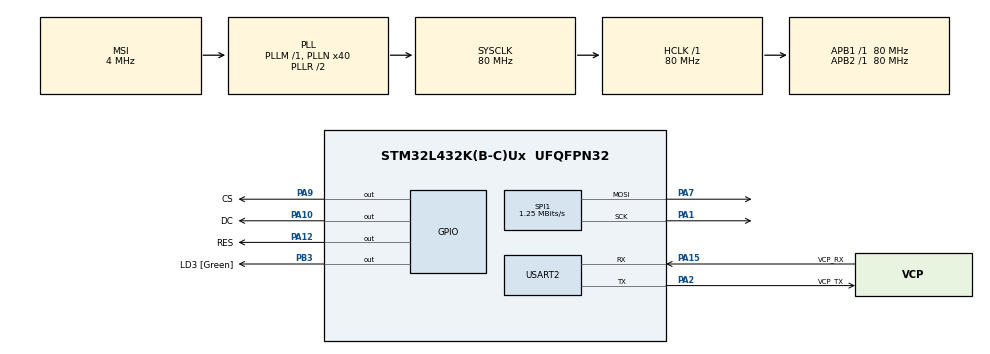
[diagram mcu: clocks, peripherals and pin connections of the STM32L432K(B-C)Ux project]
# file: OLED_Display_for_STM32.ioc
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Mcu.Family=STM32L4
Mcu.Name=STM32L432K(B-C)Ux
Mcu.Package=UFQFPN32
NVIC.PriorityGroup=NVIC_PRIORITYGROUP_4
NVIC.SPI1_IRQn=true\:0\:0\:false\:false\:true\:true\:true\:true
PA0.GPIO_Label=MCO [High speed clock in]
PA0.Mode=HSE-External-Clock-Source-for-LittleOrca
PA0.Signal=RCC_CK_IN
PA1.Mode=TX_Only_Simplex_Unidirect_Master
PA1.Signal=SPI1_SCK
PA10.GPIO_Label=DC
PA10.Signal=GPIO_Output
PA12.GPIO_Label=RES
PA12.Signal=GPIO_Output
PA13\ (JTMS-SWDIO).GPIO_Label=SWDIO
PA13\ (JTMS-SWDIO).Mode=Serial_Wire
PA13\ (JTMS-SWDIO).Signal=SYS_JTMS-SWDIO
PA14\ (JTCK-SWCLK).GPIO_Label=SWCLK
PA14\ (JTCK-SWCLK).Mode=Serial_Wire
PA14\ (JTCK-SWCLK).Signal=SYS_JTCK-SWCLK
PA15\ (JTDI).GPIO_Label=VCP_RX
PA15\ (JTDI).Mode=Asynchronous
PA15\ (JTDI).Signal=USART2_RX
PA2.GPIO_Label=VCP_TX
PA2.Mode=Asynchronous
PA2.Signal=USART2_TX
PA7.Mode=TX_Only_Simplex_Unidirect_Master
PA7.Signal=SPI1_MOSI
PA9.GPIO_Label=CS
PA9.Signal=GPIO_Output
PB3\ (JTDO-TRACESWO).GPIO_Label=LD3 [Green]
PB3\ (JTDO-TRACESWO).Signal=GPIO_Output
PC14-OSC32_IN\ (PC14).Mode=LSE-External-Oscillator
PC14-OSC32_IN\ (PC14).Signal=RCC_OSC32_IN
PC15-OSC32_OUT\ (PC15).Mode=LSE-External-Oscillator
PC15-OSC32_OUT\ (PC15).Signal=RCC_OSC32_OUT
ProjectManager.HeapSize=0x200
ProjectManager.StackSize=0x400
ProjectManager.TargetToolchain=STM32CubeIDE
RCC.AHBFreq_Value=80000000
RCC.APB1Freq_Value=80000000
RCC.APB1TimFreq_Value=80000000
RCC.APB2Freq_Value=80000000
RCC.APB2TimFreq_Value=80000000
RCC.CortexFreq_Value=80000000
RCC.HCLKFreq_Value=80000000
RCC.HSE_VALUE=8000000
RCC.HSI16_VALUE=16000000
RCC.HSI48_VALUE=48000000
RCC.HSI_VALUE=16000000
RCC.MSI_VALUE=4000000
RCC.PLLMUL=RCC_PLLMUL_4
RCC.PLLN=40
RCC.SYSCLKFreq_VALUE=80000000
RCC.SYSCLKSource=RCC_SYSCLKSOURCE_PLLCLK
RCC.VCOOutputFreq_Value=160000000
SPI1.BaudRatePrescaler=SPI_BAUDRATEPRESCALER_64
SPI1.CalculateBaudRate=1.25 MBits/s
SPI1.DataSize=SPI_DATASIZE_8BIT
SPI1.Direction=SPI_DIRECTION_2LINES
SPI1.Mode=SPI_MODE_MASTER
SPI1.VirtualType=VM_MASTER
USART2.VirtualMode-Asynchronous=VM_ASYNC
board=NUCLEO-L432KC

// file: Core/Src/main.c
/* USER CODE BEGIN Header */
/**
  ******************************************************************************
  * @file           : main.c
  * @brief          : Main program body
  ******************************************************************************
  * @attention
  *
  * Copyright (c) 2024 STMicroelectronics.
  * All rights reserved.
  *
  * This software is licensed under terms that can be found in the LICENSE file
  * in the root directory of this software component.
  * If no LICENSE file comes with this software, it is provided AS-IS.
  *
  ******************************************************************************
  */
/* USER CODE END Header */
#include "main.h"
#include "spi.h"
#include "usart.h"
#include "gpio.h"

/* USER CODE BEGIN Includes */
#include "oled.h"
/* USER CODE END Includes */

void SystemClock_Config(void);

int main(void) {
  /* USER CODE BEGIN 1 */
  uint8_t Msg[] = "Hello world!!!";
  /* USER CODE END 1 */

  /* MCU Configuration--------------------------------------------------------*/

  /* Reset of all peripherals, Initializes the Flash interface and the Systick. */
  HAL_Init();

  /* Configure the system clock */
  SystemClock_Config();

  /* Initialize all configured peripherals */
  MX_GPIO_Init();
  MX_SPI1_Init();
  MX_USART2_UART_Init();
  /* USER CODE BEGIN 2 */
  OLED_Init();
  OLED_Clear(0);
//  OLED_Set_Pixel(120, 10, 1);
//  OLED_Display();
//  OLED_ShowChar(1, 1, 'F', 16, 1);
  OLED_ShowString(20, 20, Msg, 8, 1);
  /* USER CODE END 2 */

  /* Infinite loop */
  while (1) {

    /* USER CODE BEGIN 3 */
    HAL_GPIO_TogglePin(LD3_GPIO_Port, LD3_Pin);
    HAL_Delay(500);
  }
  /* USER CODE END 3 */
}

void SystemClock_Config(void) {
  RCC_OscInitTypeDef RCC_OscInitStruct = {0};
  RCC_ClkInitTypeDef RCC_ClkInitStruct = {0};

  /** Configure the main internal regulator output voltage
  */
  if (HAL_PWREx_ControlVoltageScaling(PWR_REGULATOR_VOLTAGE_SCALE1) != HAL_OK) {
    Error_Handler();
  }

  /** Configure LSE Drive Capability
  */
  HAL_PWR_EnableBkUpAccess();
  __HAL_RCC_LSEDRIVE_CONFIG(RCC_LSEDRIVE_LOW);

  /** Initializes the RCC Oscillators according to the specified parameters
  * in the RCC_OscInitTypeDef structure.
  */
  RCC_OscInitStruct.OscillatorType = RCC_OSCILLATORTYPE_LSE | RCC_OSCILLATORTYPE_MSI;
  RCC_OscInitStruct.LSEState = RCC_LSE_ON;
  RCC_OscInitStruct.MSIState = RCC_MSI_ON;
  RCC_OscInitStruct.MSICalibrationValue = 0;
  RCC_OscInitStruct.MSIClockRange = RCC_MSIRANGE_6;
  RCC_OscInitStruct.PLL.PLLState = RCC_PLL_ON;
  RCC_OscInitStruct.PLL.PLLSource = RCC_PLLSOURCE_MSI;
  RCC_OscInitStruct.PLL.PLLM = 1;
  RCC_OscInitStruct.PLL.PLLN = 40;
  RCC_OscInitStruct.PLL.PLLP = RCC_PLLP_DIV7;
  RCC_OscInitStruct.PLL.PLLQ = RCC_PLLQ_DIV2;
  RCC_OscInitStruct.PLL.PLLR = RCC_PLLR_DIV2;
  if (HAL_RCC_OscConfig(&RCC_OscInitStruct) != HAL_OK) {
    Error_Handler();
  }

  /** Initializes the CPU, AHB and APB buses clocks
  */
  RCC_ClkInitStruct.ClockType = RCC_CLOCKTYPE_HCLK | RCC_CLOCKTYPE_SYSCLK
                                | RCC_CLOCKTYPE_PCLK1 | RCC_CLOCKTYPE_PCLK2;
  RCC_ClkInitStruct.SYSCLKSource = RCC_SYSCLKSOURCE_PLLCLK;
  RCC_ClkInitStruct.AHBCLKDivider = RCC_SYSCLK_DIV1;
  RCC_ClkInitStruct.APB1CLKDivider = RCC_HCLK_DIV1;
  RCC_ClkInitStruct.APB2CLKDivider = RCC_HCLK_DIV1;

  if (HAL_RCC_ClockConfig(&RCC_ClkInitStruct, FLASH_LATENCY_4) != HAL_OK) {
    Error_Handler();
  }

  /** Enable MSI Auto calibration
  */
  HAL_RCCEx_EnableMSIPLLMode();
}

void Error_Handler(void) {
  __disable_irq();
  while (1) {
  }
}
